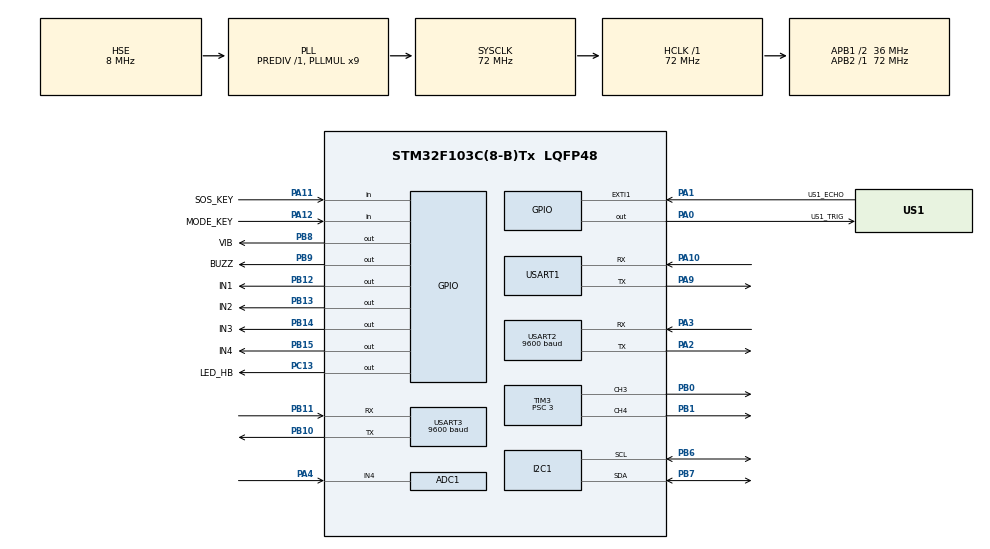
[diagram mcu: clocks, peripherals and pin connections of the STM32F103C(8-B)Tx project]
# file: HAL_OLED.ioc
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ADC1.Channel-1\#ChannelRegularConversion=ADC_CHANNEL_4
ADC1.ContinuousConvMode=ENABLE
ADC1.NbrOfConversionFlag=1
ADC1.Rank-1\#ChannelRegularConversion=1
ADC1.SamplingTime-1\#ChannelRegularConversion=ADC_SAMPLETIME_55CYCLES_5
ADC1.master=1
I2C1.I2C_Mode=I2C_Fast
Mcu.Family=STM32F1
Mcu.Name=STM32F103C(8-B)Tx
Mcu.Package=LQFP48
NVIC.EXTI1_IRQn=true\:6\:0\:true\:false\:true\:true\:true\:true
NVIC.PriorityGroup=NVIC_PRIORITYGROUP_4
NVIC.USART1_IRQn=true\:5\:0\:true\:false\:true\:true\:true\:true
NVIC.USART3_IRQn=true\:5\:0\:true\:false\:true\:true\:true\:true
PA0-WKUP.GPIO_Label=US1_TRIG
PA0-WKUP.Signal=GPIO_Output
PA1.GPIO_Label=US1_ECHO
PA1.GPIO_ModeDefaultEXTI=GPIO_MODE_IT_RISING_FALLING
PA1.GPIO_PuPd=GPIO_PULLDOWN
PA1.Signal=GPXTI1
PA10.Mode=Asynchronous
PA10.Signal=USART1_RX
PA11.GPIO_Label=SOS_KEY
PA11.GPIO_PuPd=GPIO_PULLUP
PA11.Signal=GPIO_Input
PA12.GPIO_Label=MODE_KEY
PA12.GPIO_PuPd=GPIO_PULLUP
PA12.Signal=GPIO_Input
PA13.Mode=Serial_Wire
PA13.Signal=SYS_JTMS-SWDIO
PA14.Mode=Serial_Wire
PA14.Signal=SYS_JTCK-SWCLK
PA2.Mode=Asynchronous
PA2.Signal=USART2_TX
PA3.Mode=Asynchronous
PA3.Signal=USART2_RX
PA4.Signal=ADCx_IN4
PA9.Mode=Asynchronous
PA9.Signal=USART1_TX
PB0.Signal=S_TIM3_CH3
PB1.Signal=S_TIM3_CH4
PB10.Mode=Asynchronous
PB10.Signal=USART3_TX
PB11.Mode=Asynchronous
PB11.Signal=USART3_RX
PB12.GPIO_Label=IN1
PB12.Signal=GPIO_Output
PB13.GPIO_Label=IN2
PB13.Signal=GPIO_Output
PB14.GPIO_Label=IN3
PB14.Signal=GPIO_Output
PB15.GPIO_Label=IN4
PB15.Signal=GPIO_Output
PB6.Mode=I2C
PB6.Signal=I2C1_SCL
PB7.Mode=I2C
PB7.Signal=I2C1_SDA
PB8.GPIO_Label=VIB
PB8.Signal=GPIO_Output
PB9.GPIO_Label=BUZZ
PB9.PinState=GPIO_PIN_SET
PB9.Signal=GPIO_Output
PC13-TAMPER-RTC.GPIO_Label=LED_HB
PC13-TAMPER-RTC.PinState=GPIO_PIN_SET
PC13-TAMPER-RTC.Signal=GPIO_Output
PD0-OSC_IN.Mode=HSE-External-Oscillator
PD0-OSC_IN.Signal=RCC_OSC_IN
PD1-OSC_OUT.Mode=HSE-External-Oscillator
PD1-OSC_OUT.Signal=RCC_OSC_OUT
ProjectManager.HeapSize=0x200
ProjectManager.StackSize=0x400
ProjectManager.TargetToolchain=MDK-ARM V5.32
RCC.ADCPresc=RCC_ADCPCLK2_DIV6
RCC.AHBFreq_Value=72000000
RCC.APB1CLKDivider=RCC_HCLK_DIV2
RCC.APB1Freq_Value=36000000
RCC.APB1TimFreq_Value=72000000
RCC.APB2Freq_Value=72000000
RCC.APB2TimFreq_Value=72000000
RCC.HCLKFreq_Value=72000000
RCC.PLLMUL=RCC_PLL_MUL9
RCC.PLLSourceVirtual=RCC_PLLSOURCE_HSE
RCC.SYSCLKFreq_VALUE=72000000
RCC.SYSCLKSource=RCC_SYSCLKSOURCE_PLLCLK
RCC.USBFreq_Value=72000000
SH.ADCx_IN4.0=ADC1_IN4,IN4
SH.S_TIM3_CH3.0=TIM3_CH3,PWM Generation3 CH3
SH.S_TIM3_CH4.0=TIM3_CH4,PWM Generation4 CH4
TIM3.AutoReloadPreload=TIM_AUTORELOAD_PRELOAD_ENABLE
TIM3.Channel-PWM\ Generation3\ CH3=TIM_CHANNEL_3
TIM3.Channel-PWM\ Generation4\ CH4=TIM_CHANNEL_4
TIM3.Period=999
TIM3.Prescaler=3
TIM4.Prescaler=71
USART1.VirtualMode=VM_ASYNC
USART2.BaudRate=9600
USART2.VirtualMode=VM_ASYNC
USART3.BaudRate=9600
USART3.VirtualMode=VM_ASYNC
VP_TIM4_VS_ClockSourceINT.Mode=Internal
board=custom

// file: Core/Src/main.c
/* USER CODE BEGIN Header */
/**
  ******************************************************************************
  * @file           : main.c
  * @brief          : Main program body
  ******************************************************************************
  * @attention
  *
  * Copyright (c) 2026 STMicroelectronics.
  * All rights reserved.
  *
  * This software is licensed under terms that can be found in the LICENSE file
  * in the root directory of this software component.
  * If no LICENSE file comes with this software, it is provided AS-IS.
  *
  ******************************************************************************
  */
/* USER CODE END Header */
#include "main.h"
#include "adc.h"
#include "i2c.h"
#include "tim.h"
#include "usart.h"
#include "gpio.h"

/* USER CODE BEGIN Includes */
#include "app.h"          /* 我们的唯一入口：app_init() / app_poll() */
/* USER CODE END Includes */

void SystemClock_Config(void);

int main(void)
{

  /* MCU Configuration--------------------------------------------------------*/

  /* Reset of all peripherals, Initializes the Flash interface and the Systick. */
  HAL_Init();

  /* Configure the system clock */
  SystemClock_Config();

  /* Initialize all configured peripherals */
  MX_GPIO_Init();
  MX_I2C1_Init();
  MX_ADC1_Init();
  MX_TIM3_Init();
  MX_TIM4_Init();
  MX_USART1_UART_Init();
  MX_USART2_UART_Init();
  MX_USART3_UART_Init();
  /* USER CODE BEGIN 2 */
  app_init();          /* 我们的全部初始化：日志/参数/BSP/服务/任务注册 */
  /* USER CODE END 2 */

  /* Infinite loop */
  while (1)
  {

    /* USER CODE BEGIN 3 */
    app_poll();        /* 合作式调度器：执行所有到点任务 */
  }
  /* USER CODE END 3 */
}

void SystemClock_Config(void)
{
  RCC_OscInitTypeDef RCC_OscInitStruct = {0};
  RCC_ClkInitTypeDef RCC_ClkInitStruct = {0};
  RCC_PeriphCLKInitTypeDef PeriphClkInit = {0};

  /** Initializes the RCC Oscillators according to the specified parameters
  * in the RCC_OscInitTypeDef structure.
  */
  RCC_OscInitStruct.OscillatorType = RCC_OSCILLATORTYPE_HSE;
  RCC_OscInitStruct.HSEState = RCC_HSE_ON;
  RCC_OscInitStruct.HSEPredivValue = RCC_HSE_PREDIV_DIV1;
  RCC_OscInitStruct.HSIState = RCC_HSI_ON;
  RCC_OscInitStruct.PLL.PLLState = RCC_PLL_ON;
  RCC_OscInitStruct.PLL.PLLSource = RCC_PLLSOURCE_HSE;
  RCC_OscInitStruct.PLL.PLLMUL = RCC_PLL_MUL9;
  if (HAL_RCC_OscConfig(&RCC_OscInitStruct) != HAL_OK)
  {
    Error_Handler();
  }

  /** Initializes the CPU, AHB and APB buses clocks
  */
  RCC_ClkInitStruct.ClockType = RCC_CLOCKTYPE_HCLK|RCC_CLOCKTYPE_SYSCLK
                              |RCC_CLOCKTYPE_PCLK1|RCC_CLOCKTYPE_PCLK2;
  RCC_ClkInitStruct.SYSCLKSource = RCC_SYSCLKSOURCE_PLLCLK;
  RCC_ClkInitStruct.AHBCLKDivider = RCC_SYSCLK_DIV1;
  RCC_ClkInitStruct.APB1CLKDivider = RCC_HCLK_DIV2;
  RCC_ClkInitStruct.APB2CLKDivider = RCC_HCLK_DIV1;

  if (HAL_RCC_ClockConfig(&RCC_ClkInitStruct, FLASH_LATENCY_2) != HAL_OK)
  {
    Error_Handler();
  }
  PeriphClkInit.PeriphClockSelection = RCC_PERIPHCLK_ADC;
  PeriphClkInit.AdcClockSelection = RCC_ADCPCLK2_DIV6;
  if (HAL_RCCEx_PeriphCLKConfig(&PeriphClkInit) != HAL_OK)
  {
    Error_Handler();
  }
}

void Error_Handler(void)
{
  __disable_irq();
  while (1)
  {
  }
}
